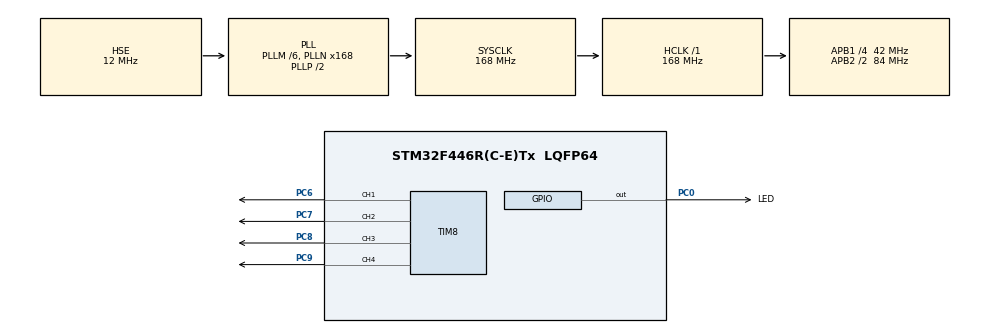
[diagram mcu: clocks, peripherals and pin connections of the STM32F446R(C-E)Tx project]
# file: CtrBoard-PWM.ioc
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Mcu.Family=STM32F4
Mcu.Name=STM32F446R(C-E)Tx
Mcu.Package=LQFP64
NVIC.PriorityGroup=NVIC_PRIORITYGROUP_4
PA13.Mode=Serial_Wire
PA13.Signal=SYS_JTMS-SWDIO
PA14.Mode=Serial_Wire
PA14.Signal=SYS_JTCK-SWCLK
PC0.GPIO_Label=LED
PC0.GPIO_ModeDefaultOutputPP=GPIO_MODE_OUTPUT_PP
PC0.GPIO_PuPd=GPIO_NOPULL
PC0.GPIO_Speed=GPIO_SPEED_FREQ_LOW
PC0.PinState=GPIO_PIN_SET
PC0.Signal=GPIO_Output
PC6.Signal=S_TIM8_CH1
PC7.Signal=S_TIM8_CH2
PC8.Signal=S_TIM8_CH3
PC9.Signal=S_TIM8_CH4
PH0-OSC_IN.Mode=HSE-External-Oscillator
PH0-OSC_IN.Signal=RCC_OSC_IN
PH1-OSC_OUT.Mode=HSE-External-Oscillator
PH1-OSC_OUT.Signal=RCC_OSC_OUT
ProjectManager.HeapSize=0x400
ProjectManager.StackSize=0x800
ProjectManager.TargetToolchain=MDK-ARM V5.27
RCC.AHBFreq_Value=168000000
RCC.APB1CLKDivider=RCC_HCLK_DIV4
RCC.APB1Freq_Value=42000000
RCC.APB1TimFreq_Value=84000000
RCC.APB2CLKDivider=RCC_HCLK_DIV2
RCC.APB2Freq_Value=84000000
RCC.APB2TimFreq_Value=168000000
RCC.CortexFreq_Value=168000000
RCC.HCLKFreq_Value=168000000
RCC.HSE_VALUE=12000000
RCC.PLLM=6
RCC.PLLN=168
RCC.PLLQ=7
RCC.PLLSAIM=6
RCC.PLLSAIN=96
RCC.PLLSAIP=RCC_PLLSAIP_DIV4
RCC.PLLSourceVirtual=RCC_PLLSOURCE_HSE
RCC.SYSCLKFreq_VALUE=168000000
RCC.SYSCLKSource=RCC_SYSCLKSOURCE_PLLCLK
RCC.USBFreq_Value=48000000
RCC.VCOOutputFreq_Value=336000000
SH.S_TIM8_CH1.0=TIM8_CH1,PWM Generation1 CH1
SH.S_TIM8_CH2.0=TIM8_CH2,PWM Generation2 CH2
SH.S_TIM8_CH3.0=TIM8_CH3,PWM Generation3 CH3
SH.S_TIM8_CH4.0=TIM8_CH4,PWM Generation4 CH4
TIM8.Channel-PWM\ Generation1\ CH1=TIM_CHANNEL_1
TIM8.Channel-PWM\ Generation2\ CH2=TIM_CHANNEL_2
TIM8.Channel-PWM\ Generation3\ CH3=TIM_CHANNEL_3
TIM8.Channel-PWM\ Generation4\ CH4=TIM_CHANNEL_4
TIM8.Pulse-PWM\ Generation1\ CH1=40000
TIM8.Pulse-PWM\ Generation2\ CH2=30000
TIM8.Pulse-PWM\ Generation3\ CH3=20000
TIM8.Pulse-PWM\ Generation4\ CH4=10000
board=custom

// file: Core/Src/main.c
/* USER CODE BEGIN Header */
/**
  ******************************************************************************
  * @file           : main.c
  * @brief          : Main program body
  ******************************************************************************
  * @attention
  *
  * <h2><center>&copy; Copyright (c) 2023 STMicroelectronics.
  * All rights reserved.</center></h2>
  *
  * This software component is licensed by ST under BSD 3-Clause license,
  * the "License"; You may not use this file except in compliance with the
  * License. You may obtain a copy of the License at:
  *                        opensource.org/licenses/BSD-3-Clause
  *
  ******************************************************************************
  */
/* USER CODE END Header */
#include "main.h"
#include "tim.h"
#include "gpio.h"

/* USER CODE BEGIN Includes */
extern TIM_HandleTypeDef htim8;
/* USER CODE END Includes */

void SystemClock_Config(void);

int main(void)
{

  /* MCU Configuration--------------------------------------------------------*/

  /* Reset of all peripherals, Initializes the Flash interface and the Systick. */
  HAL_Init();

  /* Configure the system clock */
  SystemClock_Config();

  /* Initialize all configured peripherals */
  MX_GPIO_Init();
  MX_TIM8_Init();
  /* USER CODE BEGIN 2 */

    HAL_TIM_PWM_Start(&htim8, TIM_CHANNEL_1);    /* ����PWMͨ��4 */
    HAL_TIM_PWM_Start(&htim8, TIM_CHANNEL_2);    /* ����PWMͨ��4 */
    HAL_TIM_PWM_Start(&htim8, TIM_CHANNEL_3);    /* ����PWMͨ��4 */
    HAL_TIM_PWM_Start(&htim8, TIM_CHANNEL_4);    /* ����PWMͨ��4 */

  /* USER CODE END 2 */

  /* Infinite loop */
  while (1)
  {

    /* USER CODE BEGIN 3 */
      HAL_GPIO_TogglePin(GPIOC, GPIO_PIN_0);
      HAL_Delay(100);
  }
  /* USER CODE END 3 */
}

void SystemClock_Config(void)
{
  RCC_OscInitTypeDef RCC_OscInitStruct = {0};
  RCC_ClkInitTypeDef RCC_ClkInitStruct = {0};

  /** Configure the main internal regulator output voltage
  */
  __HAL_RCC_PWR_CLK_ENABLE();
  __HAL_PWR_VOLTAGESCALING_CONFIG(PWR_REGULATOR_VOLTAGE_SCALE1);
  /** Initializes the RCC Oscillators according to the specified parameters
  * in the RCC_OscInitTypeDef structure.
  */
  RCC_OscInitStruct.OscillatorType = RCC_OSCILLATORTYPE_HSE;
  RCC_OscInitStruct.HSEState = RCC_HSE_ON;
  RCC_OscInitStruct.PLL.PLLState = RCC_PLL_ON;
  RCC_OscInitStruct.PLL.PLLSource = RCC_PLLSOURCE_HSE;
  RCC_OscInitStruct.PLL.PLLM = 6;
  RCC_OscInitStruct.PLL.PLLN = 168;
  RCC_OscInitStruct.PLL.PLLP = RCC_PLLP_DIV2;
  RCC_OscInitStruct.PLL.PLLQ = 7;
  RCC_OscInitStruct.PLL.PLLR = 2;
  if (HAL_RCC_OscConfig(&RCC_OscInitStruct) != HAL_OK)
  {
    Error_Handler();
  }
  /** Initializes the CPU, AHB and APB buses clocks
  */
  RCC_ClkInitStruct.ClockType = RCC_CLOCKTYPE_HCLK|RCC_CLOCKTYPE_SYSCLK
                              |RCC_CLOCKTYPE_PCLK1|RCC_CLOCKTYPE_PCLK2;
  RCC_ClkInitStruct.SYSCLKSource = RCC_SYSCLKSOURCE_PLLCLK;
  RCC_ClkInitStruct.AHBCLKDivider = RCC_SYSCLK_DIV1;
  RCC_ClkInitStruct.APB1CLKDivider = RCC_HCLK_DIV4;
  RCC_ClkInitStruct.APB2CLKDivider = RCC_HCLK_DIV2;

  if (HAL_RCC_ClockConfig(&RCC_ClkInitStruct, FLASH_LATENCY_5) != HAL_OK)
  {
    Error_Handler();
  }
}

void Error_Handler(void)
{
}

/************************ (C) COPYRIGHT STMicroelectronics *****END OF FILE****/
